AUTOSAR XML (schema 4-0-3)
package /ComponentTypes
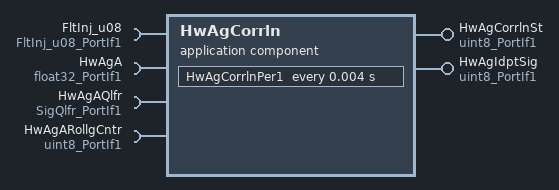
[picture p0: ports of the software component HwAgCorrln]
  application sw component type HwAgCorrln
    provide port HwAgCorrlnSt: nonqueued-sender-com-spec{data-element=Val, init-value=0}, provided-interface=uint8_PortIf1
    provide port HwAgIdptSig: nonqueued-sender-com-spec{data-element=Val, init-value=2}, provided-interface=uint8_PortIf1
    4 x require port:
      FltInj_u08: required-interface=FltInj_u08_PortIf1
      HwAgA: nonqueued-receiver-com-spec{data-element=Val, filter=data-filter-type=ALWAYS, init-value=0}, required-interface=float32_PortIf1
      HwAgAQlfr: nonqueued-receiver-com-spec{data-element=Val, filter=data-filter-type=ALWAYS, init-value=0}, required-interface=SigQlfr_PortIf1
      HwAgARollgCntr: nonqueued-receiver-com-spec{data-element=Val, filter=data-filter-type=ALWAYS, init-value=0}, required-interface=uint8_PortIf1
    behavior HwAgCorrln_InternalBehavior
      ar-typed-per-instance-memorys:
        data dHwAgCorrlnAgAAvl: sw-calibration-access=READ-ONLY, type=boolean
        data HwAgARollgCntPrev: sw-calibration-access=READ-ONLY, type=uint8
        data HwAgAStallCntPrev: sw-calibration-access=READ-ONLY, type=uint8
      timing event TMT_HwAgCorrlnPer1: start-on-event=HwAgCorrlnPer1, period=0.004
      runnable HwAgCorrlnPer1
        data-receive-point-by-arguments:
          access REC_HwAgA_Val: accessed-variable=HwAgA.Val
          access REC_HwAgAQlfr_Val: accessed-variable=HwAgAQlfr.Val
          access REC_HwAgARollgCntr_Val: accessed-variable=HwAgARollgCntr.Val
        data-send-points:
          access SEND_HwAgCorrlnSt_Val: accessed-variable=HwAgCorrlnSt.Val
          access SEND_HwAgIdptSig_Val: accessed-variable=HwAgIdptSig.Val
        sync call SC_FltInj_u08_Oper: operation=FltInj_u08.Oper, timeout=0
  swc implementation HwAgCorrln_Implementation: behavior=HwAgCorrln_InternalBehavior
    code-descriptors:
      code Default: artifact-descriptors=autosar-engineering-object={short-label=Default, category=SWSRC}
